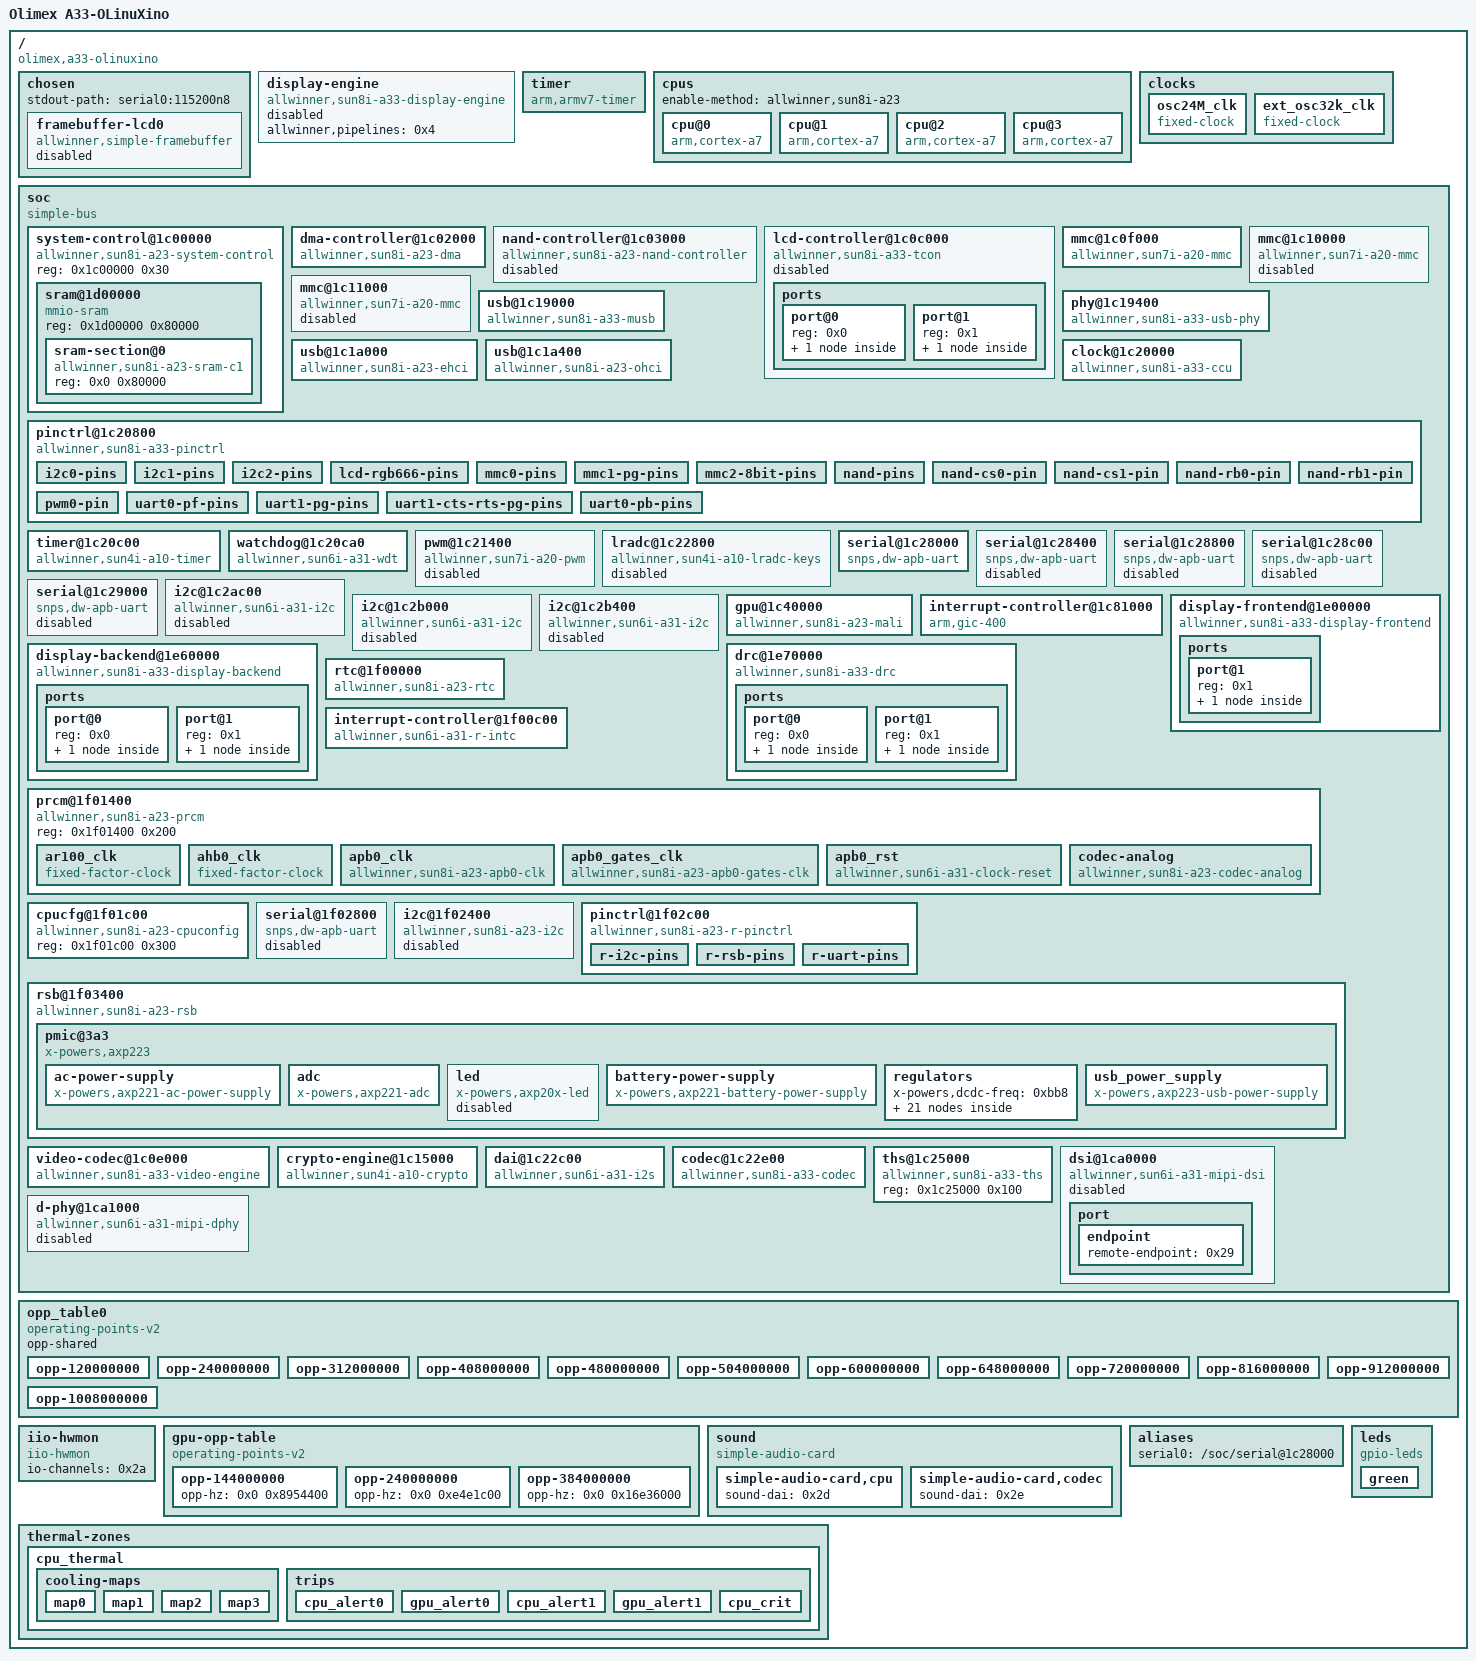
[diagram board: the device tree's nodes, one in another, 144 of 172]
/dts-v1/;

/ {
	interrupt-parent = <0x1>;
	#address-cells = <0x1>;
	#size-cells = <0x1>;
	model = "Olimex A33-OLinuXino";
	compatible = "olimex,a33-olinuxino", "allwinner,sun8i-a33";

	chosen {
		#address-cells = <0x1>;
		#size-cells = <0x1>;
		ranges;
		stdout-path = "serial0:115200n8";

		framebuffer-lcd0 {
			compatible = "allwinner,simple-framebuffer", "simple-framebuffer";
			allwinner,pipeline = "de_be0-lcd0";
			clocks = <0x2 0x26 0x2 0x28 0x2 0x57 0x2 0x55 0x2 0x54 0x2 0x62>;
			status = "disabled";
			vcc-lcd-supply = <0x3>;
			phandle = <0x38>;
		};
	};

	display-engine {
		allwinner,pipelines = <0x4>;
		status = "disabled";
		compatible = "allwinner,sun8i-a33-display-engine";
		phandle = <0x39>;
	};

	timer {
		compatible = "arm,armv7-timer";
		interrupts = <0x1 0xd 0xf08 0x1 0xe 0xf08 0x1 0xb 0xf08 0x1 0xa 0xf08>;
		clock-frequency = <0x16e3600>;
		arm,cpu-registers-not-fw-configured;
	};

	cpus {
		enable-method = "allwinner,sun8i-a23";
		#address-cells = <0x1>;
		#size-cells = <0x0>;

		cpu@0 {
			compatible = "arm,cortex-a7";
			device_type = "cpu";
			reg = <0x0>;
			clocks = <0x2 0x12>;
			clock-names = "cpu";
			operating-points-v2 = <0x5>;
			#cooling-cells = <0x2>;
			phandle = <0x30>;
		};

		cpu@1 {
			compatible = "arm,cortex-a7";
			device_type = "cpu";
			reg = <0x1>;
			clocks = <0x2 0x12>;
			clock-names = "cpu";
			operating-points-v2 = <0x5>;
			#cooling-cells = <0x2>;
			phandle = <0x31>;
		};

		cpu@2 {
			compatible = "arm,cortex-a7";
			device_type = "cpu";
			reg = <0x2>;
			clocks = <0x2 0x12>;
			clock-names = "cpu";
			operating-points-v2 = <0x5>;
			#cooling-cells = <0x2>;
			phandle = <0x32>;
		};

		cpu@3 {
			compatible = "arm,cortex-a7";
			device_type = "cpu";
			reg = <0x3>;
			clocks = <0x2 0x12>;
			clock-names = "cpu";
			operating-points-v2 = <0x5>;
			#cooling-cells = <0x2>;
			phandle = <0x33>;
		};
	};

	clocks {
		#address-cells = <0x1>;
		#size-cells = <0x1>;
		ranges;

		osc24M_clk {
			#clock-cells = <0x0>;
			compatible = "fixed-clock";
			clock-frequency = <0x16e3600>;
			clock-accuracy = <0xc350>;
			clock-output-names = "osc24M";
			phandle = <0x12>;
		};

		ext_osc32k_clk {
			#clock-cells = <0x0>;
			compatible = "fixed-clock";
			clock-frequency = <0x8000>;
			clock-accuracy = <0xc350>;
			clock-output-names = "ext-osc32k";
			phandle = <0x1e>;
		};
	};

	soc {
		compatible = "simple-bus";
		#address-cells = <0x1>;
		#size-cells = <0x1>;
		ranges;

		system-control@1c00000 {
			compatible = "allwinner,sun8i-a23-system-control";
			reg = <0x1c00000 0x30>;
			#address-cells = <0x1>;
			#size-cells = <0x1>;
			ranges;

			sram@1d00000 {
				compatible = "mmio-sram";
				reg = <0x1d00000 0x80000>;
				#address-cells = <0x1>;
				#size-cells = <0x1>;
				ranges = <0x0 0x1d00000 0x80000>;
				phandle = <0x3a>;

				sram-section@0 {
					compatible = "allwinner,sun8i-a23-sram-c1", "allwinner,sun4i-a10-sram-c1";
					reg = <0x0 0x80000>;
					phandle = <0x27>;
				};
			};
		};

		dma-controller@1c02000 {
			compatible = "allwinner,sun8i-a23-dma";
			reg = <0x1c02000 0x1000>;
			interrupts = <0x0 0x32 0x4>;
			clocks = <0x2 0x19>;
			resets = <0x2 0x6>;
			#dma-cells = <0x1>;
			phandle = <0x6>;
		};

		nand-controller@1c03000 {
			compatible = "allwinner,sun8i-a23-nand-controller";
			reg = <0x1c03000 0x1000>;
			interrupts = <0x0 0x46 0x4>;
			clocks = <0x2 0x1d 0x2 0x3b>;
			clock-names = "ahb", "mod";
			resets = <0x2 0xa>;
			reset-names = "ahb";
			dmas = <0x6 0x5>;
			dma-names = "rxtx";
			pinctrl-names = "default";
			pinctrl-0 = <0x7 0x8 0x9>;
			status = "disabled";
			#address-cells = <0x1>;
			#size-cells = <0x0>;
			phandle = <0x3b>;
		};

		lcd-controller@1c0c000 {
			reg = <0x1c0c000 0x1000>;
			interrupts = <0x0 0x56 0x4>;
			clocks = <0x2 0x26 0x2 0x57>;
			clock-names = "ahb", "tcon-ch0";
			clock-output-names = "tcon-pixel-clock";
			#clock-cells = <0x0>;
			resets = <0x2 0x13>;
			reset-names = "lcd";
			status = "disabled";
			compatible = "allwinner,sun8i-a33-tcon";
			phandle = <0x3c>;

			ports {
				#address-cells = <0x1>;
				#size-cells = <0x0>;

				port@0 {
					reg = <0x0>;
					phandle = <0x3d>;

					endpoint {
						remote-endpoint = <0xa>;
						phandle = <0x1d>;
					};
				};

				port@1 {
					reg = <0x1>;
					#address-cells = <0x1>;
					#size-cells = <0x0>;
					phandle = <0x3e>;

					endpoint@1 {
						reg = <0x1>;
						remote-endpoint = <0xb>;
						phandle = <0x29>;
					};
				};
			};
		};

		mmc@1c0f000 {
			compatible = "allwinner,sun7i-a20-mmc";
			reg = <0x1c0f000 0x1000>;
			clocks = <0x2 0x1a 0x2 0x3c 0x2 0x3e 0x2 0x3d>;
			clock-names = "ahb", "mmc", "output", "sample";
			resets = <0x2 0x7>;
			reset-names = "ahb";
			interrupts = <0x0 0x3c 0x4>;
			pinctrl-names = "default";
			pinctrl-0 = <0xc>;
			status = "okay";
			#address-cells = <0x1>;
			#size-cells = <0x0>;
			vmmc-supply = <0xd>;
			bus-width = <0x4>;
			cd-gpios = <0xe 0x1 0x4 0x1>;
			phandle = <0x3f>;
		};

		mmc@1c10000 {
			compatible = "allwinner,sun7i-a20-mmc";
			reg = <0x1c10000 0x1000>;
			clocks = <0x2 0x1b 0x2 0x3f 0x2 0x41 0x2 0x40>;
			clock-names = "ahb", "mmc", "output", "sample";
			resets = <0x2 0x8>;
			reset-names = "ahb";
			interrupts = <0x0 0x3d 0x4>;
			status = "disabled";
			#address-cells = <0x1>;
			#size-cells = <0x0>;
			phandle = <0x40>;
		};

		mmc@1c11000 {
			compatible = "allwinner,sun7i-a20-mmc";
			reg = <0x1c11000 0x1000>;
			clocks = <0x2 0x1c 0x2 0x42 0x2 0x44 0x2 0x43>;
			clock-names = "ahb", "mmc", "output", "sample";
			resets = <0x2 0x9>;
			reset-names = "ahb";
			interrupts = <0x0 0x3e 0x4>;
			status = "disabled";
			#address-cells = <0x1>;
			#size-cells = <0x0>;
			phandle = <0x41>;
		};

		usb@1c19000 {
			reg = <0x1c19000 0x400>;
			clocks = <0x2 0x22>;
			resets = <0x2 0xf>;
			interrupts = <0x0 0x47 0x4>;
			interrupt-names = "mc";
			phys = <0xf 0x0>;
			phy-names = "usb";
			extcon = <0xf 0x0>;
			dr_mode = "otg";
			status = "okay";
			compatible = "allwinner,sun8i-a33-musb";
			phandle = <0x42>;
		};

		phy@1c19400 {
			clocks = <0x2 0x4a 0x2 0x4b>;
			clock-names = "usb0_phy", "usb1_phy";
			resets = <0x2 0x0 0x2 0x1>;
			reset-names = "usb0_reset", "usb1_reset";
			status = "okay";
			#phy-cells = <0x1>;
			compatible = "allwinner,sun8i-a33-usb-phy";
			reg = <0x1c19400 0x14 0x1c1a800 0x4>;
			reg-names = "phy_ctrl", "pmu1";
			usb0_id_det-gpios = <0xe 0x1 0x3 0x0>;
			usb0_vbus_power-supply = <0x10>;
			usb0_vbus-supply = <0x11>;
			phandle = <0xf>;
		};

		usb@1c1a000 {
			compatible = "allwinner,sun8i-a23-ehci", "generic-ehci";
			reg = <0x1c1a000 0x100>;
			interrupts = <0x0 0x48 0x4>;
			clocks = <0x2 0x23>;
			resets = <0x2 0x10>;
			phys = <0xf 0x1>;
			status = "okay";
			phandle = <0x43>;
		};

		usb@1c1a400 {
			compatible = "allwinner,sun8i-a23-ohci", "generic-ohci";
			reg = <0x1c1a400 0x100>;
			interrupts = <0x0 0x49 0x4>;
			clocks = <0x2 0x24 0x2 0x4e>;
			resets = <0x2 0x11>;
			phys = <0xf 0x1>;
			status = "okay";
			phandle = <0x44>;
		};

		clock@1c20000 {
			reg = <0x1c20000 0x400>;
			clocks = <0x12 0x13 0x0>;
			clock-names = "hosc", "losc";
			#clock-cells = <0x1>;
			#reset-cells = <0x1>;
			compatible = "allwinner,sun8i-a33-ccu";
			phandle = <0x2>;
		};

		pinctrl@1c20800 {
			reg = <0x1c20800 0x400>;
			clocks = <0x2 0x30 0x12 0x13 0x0>;
			clock-names = "apb", "hosc", "losc";
			gpio-controller;
			interrupt-controller;
			#interrupt-cells = <0x3>;
			#gpio-cells = <0x3>;
			compatible = "allwinner,sun8i-a33-pinctrl";
			interrupts = <0x0 0xf 0x4 0x0 0x11 0x4>;
			phandle = <0xe>;

			i2c0-pins {
				pins = "PH2", "PH3";
				function = "i2c0";
				phandle = <0x15>;
			};

			i2c1-pins {
				pins = "PH4", "PH5";
				function = "i2c1";
				phandle = <0x16>;
			};

			i2c2-pins {
				pins = "PE12", "PE13";
				function = "i2c2";
				phandle = <0x17>;
			};

			lcd-rgb666-pins {
				pins = "PD2", "PD3", "PD4", "PD5", "PD6", "PD7", "PD10", "PD11", "PD12", "PD13", "PD14", "PD15", "PD18", "PD19", "PD20", "PD21", "PD22", "PD23", "PD24", "PD25", "PD26", "PD27";
				function = "lcd0";
				phandle = <0x45>;
			};

			mmc0-pins {
				pins = "PF0", "PF1", "PF2", "PF3", "PF4", "PF5";
				function = "mmc0";
				drive-strength = <0x1e>;
				bias-pull-up;
				phandle = <0xc>;
			};

			mmc1-pg-pins {
				pins = "PG0", "PG1", "PG2", "PG3", "PG4", "PG5";
				function = "mmc1";
				drive-strength = <0x1e>;
				bias-pull-up;
				phandle = <0x46>;
			};

			mmc2-8bit-pins {
				pins = "PC5", "PC6", "PC8", "PC9", "PC10", "PC11", "PC12", "PC13", "PC14", "PC15", "PC16";
				function = "mmc2";
				drive-strength = <0x1e>;
				bias-pull-up;
				phandle = <0x47>;
			};

			nand-pins {
				pins = "PC0", "PC1", "PC2", "PC5", "PC8", "PC9", "PC10", "PC11", "PC12", "PC13", "PC14", "PC15";
				function = "nand0";
				phandle = <0x7>;
			};

			nand-cs0-pin {
				pins = "PC4";
				function = "nand0";
				bias-pull-up;
				phandle = <0x8>;
			};

			nand-cs1-pin {
				pins = "PC3";
				function = "nand0";
				bias-pull-up;
				phandle = <0x48>;
			};

			nand-rb0-pin {
				pins = "PC6";
				function = "nand0";
				bias-pull-up;
				phandle = <0x9>;
			};

			nand-rb1-pin {
				pins = "PC7";
				function = "nand0";
				bias-pull-up;
				phandle = <0x49>;
			};

			pwm0-pin {
				pins = "PH0";
				function = "pwm0";
				phandle = <0x4a>;
			};

			uart0-pf-pins {
				pins = "PF2", "PF4";
				function = "uart0";
				phandle = <0x4b>;
			};

			uart1-pg-pins {
				pins = "PG6", "PG7";
				function = "uart1";
				phandle = <0x4c>;
			};

			uart1-cts-rts-pg-pins {
				pins = "PG8", "PG9";
				function = "uart1";
				phandle = <0x4d>;
			};

			uart0-pb-pins {
				pins = "PB0", "PB1";
				function = "uart0";
				phandle = <0x14>;
			};
		};

		timer@1c20c00 {
			compatible = "allwinner,sun4i-a10-timer";
			reg = <0x1c20c00 0xa0>;
			interrupts = <0x0 0x12 0x4 0x0 0x13 0x4>;
			clocks = <0x12>;
		};

		watchdog@1c20ca0 {
			compatible = "allwinner,sun6i-a31-wdt";
			reg = <0x1c20ca0 0x20>;
			interrupts = <0x0 0x19 0x4>;
			phandle = <0x4e>;
		};

		pwm@1c21400 {
			compatible = "allwinner,sun7i-a20-pwm";
			reg = <0x1c21400 0xc>;
			clocks = <0x12>;
			#pwm-cells = <0x3>;
			status = "disabled";
			phandle = <0x4f>;
		};

		lradc@1c22800 {
			compatible = "allwinner,sun4i-a10-lradc-keys";
			reg = <0x1c22800 0x100>;
			interrupts = <0x0 0x1e 0x4>;
			status = "disabled";
			phandle = <0x50>;
		};

		serial@1c28000 {
			compatible = "snps,dw-apb-uart";
			reg = <0x1c28000 0x400>;
			interrupts = <0x0 0x0 0x4>;
			reg-shift = <0x2>;
			reg-io-width = <0x4>;
			clocks = <0x2 0x36>;
			resets = <0x2 0x23>;
			dmas = <0x6 0x6 0x6 0x6>;
			dma-names = "rx", "tx";
			status = "okay";
			pinctrl-names = "default";
			pinctrl-0 = <0x14>;
			phandle = <0x51>;
		};

		serial@1c28400 {
			compatible = "snps,dw-apb-uart";
			reg = <0x1c28400 0x400>;
			interrupts = <0x0 0x1 0x4>;
			reg-shift = <0x2>;
			reg-io-width = <0x4>;
			clocks = <0x2 0x37>;
			resets = <0x2 0x24>;
			dmas = <0x6 0x7 0x6 0x7>;
			dma-names = "rx", "tx";
			status = "disabled";
			phandle = <0x52>;
		};

		serial@1c28800 {
			compatible = "snps,dw-apb-uart";
			reg = <0x1c28800 0x400>;
			interrupts = <0x0 0x2 0x4>;
			reg-shift = <0x2>;
			reg-io-width = <0x4>;
			clocks = <0x2 0x38>;
			resets = <0x2 0x25>;
			dmas = <0x6 0x8 0x6 0x8>;
			dma-names = "rx", "tx";
			status = "disabled";
			phandle = <0x53>;
		};

		serial@1c28c00 {
			compatible = "snps,dw-apb-uart";
			reg = <0x1c28c00 0x400>;
			interrupts = <0x0 0x3 0x4>;
			reg-shift = <0x2>;
			reg-io-width = <0x4>;
			clocks = <0x2 0x39>;
			resets = <0x2 0x26>;
			dmas = <0x6 0x9 0x6 0x9>;
			dma-names = "rx", "tx";
			status = "disabled";
			phandle = <0x54>;
		};

		serial@1c29000 {
			compatible = "snps,dw-apb-uart";
			reg = <0x1c29000 0x400>;
			interrupts = <0x0 0x4 0x4>;
			reg-shift = <0x2>;
			reg-io-width = <0x4>;
			clocks = <0x2 0x3a>;
			resets = <0x2 0x27>;
			dmas = <0x6 0xa 0x6 0xa>;
			dma-names = "rx", "tx";
			status = "disabled";
			phandle = <0x55>;
		};

		i2c@1c2ac00 {
			compatible = "allwinner,sun6i-a31-i2c";
			reg = <0x1c2ac00 0x400>;
			interrupts = <0x0 0x6 0x4>;
			clocks = <0x2 0x33>;
			resets = <0x2 0x20>;
			pinctrl-names = "default";
			pinctrl-0 = <0x15>;
			status = "disabled";
			#address-cells = <0x1>;
			#size-cells = <0x0>;
			phandle = <0x56>;
		};

		i2c@1c2b000 {
			compatible = "allwinner,sun6i-a31-i2c";
			reg = <0x1c2b000 0x400>;
			interrupts = <0x0 0x7 0x4>;
			clocks = <0x2 0x34>;
			resets = <0x2 0x21>;
			pinctrl-names = "default";
			pinctrl-0 = <0x16>;
			status = "disabled";
			#address-cells = <0x1>;
			#size-cells = <0x0>;
			phandle = <0x57>;
		};

		i2c@1c2b400 {
			compatible = "allwinner,sun6i-a31-i2c";
			reg = <0x1c2b400 0x400>;
			interrupts = <0x0 0x8 0x4>;
			clocks = <0x2 0x35>;
			resets = <0x2 0x22>;
			pinctrl-names = "default";
			pinctrl-0 = <0x17>;
			status = "disabled";
			#address-cells = <0x1>;
			#size-cells = <0x0>;
			phandle = <0x58>;
		};

		gpu@1c40000 {
			compatible = "allwinner,sun8i-a23-mali", "allwinner,sun7i-a20-mali", "arm,mali-400";
			reg = <0x1c40000 0x10000>;
			interrupts = <0x0 0x61 0x4 0x0 0x62 0x4 0x0 0x63 0x4 0x0 0x64 0x4 0x0 0x66 0x4 0x0 0x67 0x4 0x0 0x65 0x4>;
			interrupt-names = "gp", "gpmmu", "pp0", "ppmmu0", "pp1", "ppmmu1", "pmu";
			clocks = <0x2 0x2a 0x2 0x63>;
			clock-names = "bus", "core";
			resets = <0x2 0x17>;
			#cooling-cells = <0x2>;
			assigned-clocks = <0x2 0x63>;
			assigned-clock-rates = <0x16e36000>;
			operating-points-v2 = <0x18>;
			phandle = <0x36>;
		};

		interrupt-controller@1c81000 {
			compatible = "arm,gic-400";
			reg = <0x1c81000 0x1000 0x1c82000 0x2000 0x1c84000 0x2000 0x1c86000 0x2000>;
			interrupt-controller;
			#interrupt-cells = <0x3>;
			interrupts = <0x1 0x9 0xf04>;
			phandle = <0x1>;
		};

		display-frontend@1e00000 {
			reg = <0x1e00000 0x20000>;
			interrupts = <0x0 0x5d 0x4>;
			clocks = <0x2 0x29 0x2 0x56 0x2 0x53>;
			clock-names = "ahb", "mod", "ram";
			resets = <0x2 0x16>;
			compatible = "allwinner,sun8i-a33-display-frontend";
			phandle = <0x4>;

			ports {
				#address-cells = <0x1>;
				#size-cells = <0x0>;

				port@1 {
					reg = <0x1>;
					phandle = <0x59>;

					endpoint {
						remote-endpoint = <0x19>;
						phandle = <0x1a>;
					};
				};
			};
		};

		display-backend@1e60000 {
			reg = <0x1e60000 0x10000 0x1e80000 0x1000>;
			interrupts = <0x0 0x5f 0x4>;
			clocks = <0x2 0x28 0x2 0x55 0x2 0x54 0x2 0x2e>;
			clock-names = "ahb", "mod", "ram", "sat";
			resets = <0x2 0x15 0x2 0x1b>;
			compatible = "allwinner,sun8i-a33-display-backend";
			reg-names = "be", "sat";
			reset-names = "be", "sat";
			assigned-clocks = <0x2 0x55>;
			assigned-clock-rates = <0x11e1a300>;
			phandle = <0x5a>;

			ports {
				#address-cells = <0x1>;
				#size-cells = <0x0>;

				port@0 {
					reg = <0x0>;
					phandle = <0x5b>;

					endpoint {
						remote-endpoint = <0x1a>;
						phandle = <0x19>;
					};
				};

				port@1 {
					reg = <0x1>;
					phandle = <0x5c>;

					endpoint {
						remote-endpoint = <0x1b>;
						phandle = <0x1c>;
					};
				};
			};
		};

		drc@1e70000 {
			reg = <0x1e70000 0x10000>;
			interrupts = <0x0 0x5b 0x4>;
			clocks = <0x2 0x2d 0x2 0x62 0x2 0x52>;
			clock-names = "ahb", "mod", "ram";
			resets = <0x2 0x1a>;
			assigned-clocks = <0x2 0x62>;
			assigned-clock-rates = <0x11e1a300>;
			compatible = "allwinner,sun8i-a33-drc";
			phandle = <0x5d>;

			ports {
				#address-cells = <0x1>;
				#size-cells = <0x0>;

				port@0 {
					reg = <0x0>;
					phandle = <0x5e>;

					endpoint {
						remote-endpoint = <0x1c>;
						phandle = <0x1b>;
					};
				};

				port@1 {
					reg = <0x1>;
					phandle = <0x5f>;

					endpoint {
						remote-endpoint = <0x1d>;
						phandle = <0xa>;
					};
				};
			};
		};

		rtc@1f00000 {
			compatible = "allwinner,sun8i-a23-rtc";
			reg = <0x1f00000 0x400>;
			interrupts = <0x0 0x28 0x4 0x0 0x29 0x4>;
			clock-output-names = "osc32k", "osc32k-out";
			clocks = <0x1e>;
			#clock-cells = <0x1>;
			phandle = <0x13>;
		};

		interrupt-controller@1f00c00 {
			compatible = "allwinner,sun6i-a31-r-intc";
			interrupt-controller;
			#interrupt-cells = <0x2>;
			reg = <0x1f00c00 0x400>;
			interrupts = <0x0 0x20 0x4>;
			phandle = <0x26>;
		};

		prcm@1f01400 {
			compatible = "allwinner,sun8i-a23-prcm";
			reg = <0x1f01400 0x200>;

			ar100_clk {
				compatible = "fixed-factor-clock";
				#clock-cells = <0x0>;
				clock-div = <0x1>;
				clock-mult = <0x1>;
				clocks = <0x12>;
				clock-output-names = "ar100";
				phandle = <0x1f>;
			};

			ahb0_clk {
				compatible = "fixed-factor-clock";
				#clock-cells = <0x0>;
				clock-div = <0x1>;
				clock-mult = <0x1>;
				clocks = <0x1f>;
				clock-output-names = "ahb0";
				phandle = <0x20>;
			};

			apb0_clk {
				compatible = "allwinner,sun8i-a23-apb0-clk";
				#clock-cells = <0x0>;
				clocks = <0x20>;
				clock-output-names = "apb0";
				phandle = <0x21>;
			};

			apb0_gates_clk {
				compatible = "allwinner,sun8i-a23-apb0-gates-clk";
				#clock-cells = <0x1>;
				clocks = <0x21>;
				clock-output-names = "apb0_pio", "apb0_timer", "apb0_rsb", "apb0_uart", "apb0_i2c";
				phandle = <0x22>;
			};

			apb0_rst {
				compatible = "allwinner,sun6i-a31-clock-reset";
				#reset-cells = <0x1>;
				phandle = <0x23>;
			};

			codec-analog {
				compatible = "allwinner,sun8i-a23-codec-analog";
				phandle = <0x2c>;
			};
		};

		cpucfg@1f01c00 {
			compatible = "allwinner,sun8i-a23-cpuconfig";
			reg = <0x1f01c00 0x300>;
		};

		serial@1f02800 {
			compatible = "snps,dw-apb-uart";
			reg = <0x1f02800 0x400>;
			interrupts = <0x0 0x26 0x4>;
			reg-shift = <0x2>;
			reg-io-width = <0x4>;
			clocks = <0x22 0x4>;
			resets = <0x23 0x4>;
			status = "disabled";
			phandle = <0x60>;
		};

		i2c@1f02400 {
			compatible = "allwinner,sun8i-a23-i2c", "allwinner,sun6i-a31-i2c";
			reg = <0x1f02400 0x400>;
			interrupts = <0x0 0x2c 0x4>;
			pinctrl-names = "default";
			pinctrl-0 = <0x24>;
			clocks = <0x22 0x6>;
			resets = <0x23 0x6>;
			status = "disabled";
			#address-cells = <0x1>;
			#size-cells = <0x0>;
			phandle = <0x61>;
		};

		pinctrl@1f02c00 {
			compatible = "allwinner,sun8i-a23-r-pinctrl";
			reg = <0x1f02c00 0x400>;
			interrupts = <0x0 0x2d 0x4>;
			clocks = <0x22 0x0 0x12 0x13 0x0>;
			clock-names = "apb", "hosc", "losc";
			resets = <0x23 0x0>;
			gpio-controller;
			interrupt-controller;
			#interrupt-cells = <0x3>;
			#gpio-cells = <0x3>;
			phandle = <0x62>;

			r-i2c-pins {
				pins = "PL0", "PL1";
				function = "s_i2c";
				bias-pull-up;
				phandle = <0x24>;
			};

			r-rsb-pins {
				pins = "PL0", "PL1";
				function = "s_rsb";
				drive-strength = <0x14>;
				bias-pull-up;
				phandle = <0x25>;
			};

			r-uart-pins {
				pins = "PL2", "PL3";
				function = "s_uart";
				phandle = <0x63>;
			};
		};

		rsb@1f03400 {
			compatible = "allwinner,sun8i-a23-rsb";
			reg = <0x1f03400 0x400>;
			interrupts = <0x0 0x27 0x4>;
			clocks = <0x22 0x3>;
			clock-frequency = <0x2dc6c0>;
			resets = <0x23 0x3>;
			pinctrl-names = "default";
			pinctrl-0 = <0x25>;
			status = "okay";
			#address-cells = <0x1>;
			#size-cells = <0x0>;
			phandle = <0x64>;

			pmic@3a3 {
				compatible = "x-powers,axp223";
				reg = <0x3a3>;
				interrupt-parent = <0x26>;
				interrupts = <0x0 0x8>;
				eldoin-supply = <0xd>;
				x-powers,drive-vbus-en;
				interrupt-controller;
				#interrupt-cells = <0x1>;
				phandle = <0x65>;

				ac-power-supply {
					compatible = "x-powers,axp221-ac-power-supply";
					status = "okay";
					phandle = <0x66>;
				};

				adc {
					compatible = "x-powers,axp221-adc";
					#io-channel-cells = <0x1>;
					phandle = <0x67>;
				};

				led {
					compatible = "x-powers,axp20x-led";
					status = "disabled";
					phandle = <0x68>;
				};

				battery-power-supply {
					compatible = "x-powers,axp221-battery-power-supply";
					status = "okay";
					phandle = <0x69>;
				};

				regulators {
					x-powers,dcdc-freq = <0xbb8>;

					dcdc1 {
						regulator-name = "vcc-3v3";
						regulator-always-on;
						regulator-min-microvolt = <0x325aa0>;
						regulator-max-microvolt = <0x325aa0>;
						phandle = <0xd>;
					};

					dcdc2 {
						regulator-name = "vdd-sys";
						regulator-always-on;
						regulator-min-microvolt = <0xdbba0>;
						regulator-max-microvolt = <0x155cc0>;
						phandle = <0x6a>;
					};

					dcdc3 {
						regulator-name = "vdd-cpu";
						regulator-always-on;
						regulator-min-microvolt = <0xdbba0>;
						regulator-max-microvolt = <0x155cc0>;
						phandle = <0x6b>;
					};

					dcdc4 {
						regulator-name = "dcdc4";
						phandle = <0x6c>;
					};

					dcdc5 {
						regulator-name = "vcc-dram";
						regulator-always-on;
						regulator-min-microvolt = <0x16e360>;
						regulator-max-microvolt = <0x16e360>;
						phandle = <0x6d>;
					};

					dc1sw {
						regulator-name = "vcc-lcd";
						phandle = <0x3>;
					};

					dc5ldo {
						regulator-name = "vdd-cpus";
						regulator-always-on;
						regulator-min-microvolt = <0xdbba0>;
						regulator-max-microvolt = <0x155cc0>;
						phandle = <0x6e>;
					};

					aldo1 {
						regulator-name = "vcc-io";
						regulator-always-on;
						regulator-min-microvolt = <0x325aa0>;
						regulator-max-microvolt = <0x325aa0>;
						phandle = <0x6f>;
					};

					aldo2 {
						regulator-name = "vdd-dll";
						regulator-always-on;
						regulator-min-microvolt = <0x23dbb0>;
						regulator-max-microvolt = <0x286f90>;
						phandle = <0x70>;
					};

					aldo3 {
						regulator-name = "vcc-avcc";
						regulator-always-on;
						regulator-min-microvolt = <0x325aa0>;
						regulator-max-microvolt = <0x325aa0>;
						phandle = <0x71>;
					};

					dldo1 {
						regulator-name = "dldo1";
						phandle = <0x72>;
					};

					dldo2 {
						regulator-name = "dldo2";
						phandle = <0x73>;
					};

					dldo3 {
						regulator-name = "dldo3";
						phandle = <0x74>;
					};

					dldo4 {
						regulator-name = "dldo4";
						phandle = <0x75>;
					};

					eldo1 {
						regulator-name = "eldo1";
						phandle = <0x76>;
					};

					eldo2 {
						regulator-name = "eldo2";
						phandle = <0x77>;
					};

					eldo3 {
						regulator-name = "eldo3";
						phandle = <0x78>;
					};

					ldo_io0 {
						regulator-name = "ldo_io0";
						status = "disabled";
						phandle = <0x79>;
					};

					ldo_io1 {
						regulator-name = "ldo_io1";
						status = "disabled";
						phandle = <0x7a>;
					};

					rtc_ldo {
						regulator-always-on;
						regulator-min-microvolt = <0x2dc6c0>;
						regulator-max-microvolt = <0x2dc6c0>;
						regulator-name = "vcc-rtc";
						phandle = <0x7b>;
					};

					drivevbus {
						regulator-name = "usb0-vbus";
						status = "okay";
						phandle = <0x11>;
					};
				};

				usb_power_supply {
					compatible = "x-powers,axp223-usb-power-supply";
					status = "okay";
					phandle = <0x10>;
				};
			};
		};

		video-codec@1c0e000 {
			compatible = "allwinner,sun8i-a33-video-engine";
			reg = <0x1c0e000 0x1000>;
			clocks = <0x2 0x25 0x2 0x5b 0x2 0x50>;
			clock-names = "ahb", "mod", "ram";
			resets = <0x2 0x12>;
			interrupts = <0x0 0x3a 0x4>;
			allwinner,sram = <0x27 0x1>;
		};

		crypto-engine@1c15000 {
			compatible = "allwinner,sun4i-a10-crypto";
			reg = <0x1c15000 0x1000>;
			interrupts = <0x0 0x50 0x4>;
			clocks = <0x2 0x18 0x2 0x45>;
			clock-names = "ahb", "mod";
			resets = <0x2 0x5>;
			reset-names = "ahb";
			phandle = <0x7c>;
		};

		dai@1c22c00 {
			#sound-dai-cells = <0x0>;
			compatible = "allwinner,sun6i-a31-i2s";
			reg = <0x1c22c00 0x200>;
			interrupts = <0x0 0x1d 0x4>;
			clocks = <0x2 0x2f 0x2 0x5c>;
			clock-names = "apb", "mod";
			resets = <0x2 0x1d>;
			dmas = <0x6 0xf 0x6 0xf>;
			dma-names = "rx", "tx";
			status = "okay";
			phandle = <0x2d>;
		};

		codec@1c22e00 {
			#sound-dai-cells = <0x0>;
			compatible = "allwinner,sun8i-a33-codec";
			reg = <0x1c22e00 0x400>;
			interrupts = <0x0 0x1d 0x4>;
			clocks = <0x2 0x2f 0x2 0x5c>;
			clock-names = "bus", "mod";
			status = "okay";
			phandle = <0x2e>;
		};

		ths@1c25000 {
			compatible = "allwinner,sun8i-a33-ths";
			reg = <0x1c25000 0x100>;
			#thermal-sensor-cells = <0x0>;
			#io-channel-cells = <0x0>;
			phandle = <0x2a>;
		};

		dsi@1ca0000 {
			compatible = "allwinner,sun6i-a31-mipi-dsi";
			reg = <0x1ca0000 0x1000>;
			interrupts = <0x0 0x59 0x4>;
			clocks = <0x2 0x17 0x2 0x60>;
			clock-names = "bus", "mod";
			resets = <0x2 0x4>;
			phys = <0x28>;
			phy-names = "dphy";
			status = "disabled";
			#address-cells = <0x1>;
			#size-cells = <0x0>;
			phandle = <0x7d>;

			port {

				endpoint {
					remote-endpoint = <0x29>;
					phandle = <0xb>;
				};
			};
		};

		d-phy@1ca1000 {
			compatible = "allwinner,sun6i-a31-mipi-dphy";
			reg = <0x1ca1000 0x1000>;
			clocks = <0x2 0x17 0x2 0x61>;
			clock-names = "bus", "mod";
			resets = <0x2 0x4>;
			status = "disabled";
			#phy-cells = <0x0>;
			phandle = <0x28>;
		};
	};

	opp_table0 {
		compatible = "operating-points-v2";
		opp-shared;
		phandle = <0x5>;

		opp-120000000 {
			opp-hz = <0x0 0x7270e00>;
			opp-microvolt = <0xfde80>;
			clock-latency-ns = <0x3b9b0>;
		};

		opp-240000000 {
			opp-hz = <0x0 0xe4e1c00>;
			opp-microvolt = <0xfde80>;
			clock-latency-ns = <0x3b9b0>;
		};

		opp-312000000 {
			opp-hz = <0x0 0x1298be00>;
			opp-microvolt = <0xfde80>;
			clock-latency-ns = <0x3b9b0>;
		};

		opp-408000000 {
			opp-hz = <0x0 0x18519600>;
			opp-microvolt = <0xfde80>;
			clock-latency-ns = <0x3b9b0>;
		};

		opp-480000000 {
			opp-hz = <0x0 0x1c9c3800>;
			opp-microvolt = <0xfde80>;
			clock-latency-ns = <0x3b9b0>;
		};

		opp-504000000 {
			opp-hz = <0x0 0x1e0a6e00>;
			opp-microvolt = <0xfde80>;
			clock-latency-ns = <0x3b9b0>;
		};

		opp-600000000 {
			opp-hz = <0x0 0x23c34600>;
			opp-microvolt = <0xfde80>;
			clock-latency-ns = <0x3b9b0>;
		};

		opp-648000000 {
			opp-hz = <0x0 0x269fb200>;
			opp-microvolt = <0xfde80>;
			clock-latency-ns = <0x3b9b0>;
		};

		opp-720000000 {
			opp-hz = <0x0 0x2aea5400>;
			opp-microvolt = <0x10c8e0>;
			clock-latency-ns = <0x3b9b0>;
		};

		opp-816000000 {
			opp-hz = <0x0 0x30a32c00>;
			opp-microvolt = <0x10c8e0>;
			clock-latency-ns = <0x3b9b0>;
		};

		opp-912000000 {
			opp-hz = <0x0 0x365c0400>;
			opp-microvolt = <0x124f80>;
			clock-latency-ns = <0x3b9b0>;
		};

		opp-1008000000 {
			opp-hz = <0x0 0x3c14dc00>;
			opp-microvolt = <0x124f80>;
			clock-latency-ns = <0x3b9b0>;
		};
	};

	iio-hwmon {
		compatible = "iio-hwmon";
		io-channels = <0x2a>;
	};

	gpu-opp-table {
		compatible = "operating-points-v2";
		phandle = <0x18>;

		opp-144000000 {
			opp-hz = <0x0 0x8954400>;
		};

		opp-240000000 {
			opp-hz = <0x0 0xe4e1c00>;
		};

		opp-384000000 {
			opp-hz = <0x0 0x16e36000>;
		};
	};

	sound {
		compatible = "simple-audio-card";
		simple-audio-card,name = "sun8i-a33-audio";
		simple-audio-card,format = "i2s";
		simple-audio-card,frame-master = <0x2b>;
		simple-audio-card,bitclock-master = <0x2b>;
		simple-audio-card,mclk-fs = <0x80>;
		simple-audio-card,aux-devs = <0x2c>;
		simple-audio-card,routing = "Left DAC", "AIF1 Slot 0 Left", "Right DAC", "AIF1 Slot 0 Right", "HP", "HPCOM", "Headphone Jack", "HP", "MIC1", "Microphone Jack", "Microphone Jack", "MBIAS";
		status = "okay";
		simple-audio-card,widgets = "Microphone", "Microphone Jack", "Headphone", "Headphone Jack";
		phandle = <0x7e>;

		simple-audio-card,cpu {
			sound-dai = <0x2d>;
		};

		simple-audio-card,codec {
			sound-dai = <0x2e>;
			phandle = <0x2b>;
		};
	};

	thermal-zones {

		cpu_thermal {
			polling-delay-passive = <0xfa>;
			polling-delay = <0x3e8>;
			thermal-sensors = <0x2a>;

			cooling-maps {

				map0 {
					trip = <0x2f>;
					cooling-device = <0x30 0xffffffff 0xffffffff 0x31 0xffffffff 0xffffffff 0x32 0xffffffff 0xffffffff 0x33 0xffffffff 0xffffffff>;
				};

				map1 {
					trip = <0x34>;
					cooling-device = <0x30 0xffffffff 0xffffffff 0x31 0xffffffff 0xffffffff 0x32 0xffffffff 0xffffffff 0x33 0xffffffff 0xffffffff>;
				};

				map2 {
					trip = <0x35>;
					cooling-device = <0x36 0x1 0xffffffff>;
				};

				map3 {
					trip = <0x37>;
					cooling-device = <0x36 0x2 0xffffffff>;
				};
			};

			trips {

				cpu_alert0 {
					temperature = <0x124f8>;
					hysteresis = <0x7d0>;
					type = "passive";
					phandle = <0x2f>;
				};

				gpu_alert0 {
					temperature = <0x14c08>;
					hysteresis = <0x7d0>;
					type = "passive";
					phandle = <0x35>;
				};

				cpu_alert1 {
					temperature = <0x15f90>;
					hysteresis = <0x7d0>;
					type = "hot";
					phandle = <0x34>;
				};

				gpu_alert1 {
					temperature = <0x17318>;
					hysteresis = <0x7d0>;
					type = "hot";
					phandle = <0x37>;
				};

				cpu_crit {
					temperature = <0x1adb0>;
					hysteresis = <0x7d0>;
					type = "critical";
					phandle = <0x7f>;
				};
			};
		};
	};

	aliases {
		serial0 = "/soc/serial@1c28000";
	};

	leds {
		compatible = "gpio-leds";

		green {
			label = "a33-olinuxino:green:usr";
			gpios = <0xe 0x1 0x7 0x0>;
		};
	};

	__symbols__ {
		simplefb_lcd = "/chosen/framebuffer-lcd0";
		de = "/display-engine";
		cpu0 = "/cpus/cpu@0";
		cpu1 = "/cpus/cpu@1";
		cpu2 = "/cpus/cpu@2";
		cpu3 = "/cpus/cpu@3";
		osc24M = "/clocks/osc24M_clk";
		ext_osc32k = "/clocks/ext_osc32k_clk";
		sram_c = "/soc/system-control@1c00000/sram@1d00000";
		ve_sram = "/soc/system-control@1c00000/sram@1d00000/sram-section@0";
		dma = "/soc/dma-controller@1c02000";
		nfc = "/soc/nand-controller@1c03000";
		tcon0 = "/soc/lcd-controller@1c0c000";
		tcon0_in = "/soc/lcd-controller@1c0c000/ports/port@0";
		tcon0_in_drc0 = "/soc/lcd-controller@1c0c000/ports/port@0/endpoint";
		tcon0_out = "/soc/lcd-controller@1c0c000/ports/port@1";
		tcon0_out_dsi = "/soc/lcd-controller@1c0c000/ports/port@1/endpoint@1";
		mmc0 = "/soc/mmc@1c0f000";
		mmc1 = "/soc/mmc@1c10000";
		mmc2 = "/soc/mmc@1c11000";
		usb_otg = "/soc/usb@1c19000";
		usbphy = "/soc/phy@1c19400";
		ehci0 = "/soc/usb@1c1a000";
		ohci0 = "/soc/usb@1c1a400";
		ccu = "/soc/clock@1c20000";
		pio = "/soc/pinctrl@1c20800";
		i2c0_pins = "/soc/pinctrl@1c20800/i2c0-pins";
		i2c1_pins = "/soc/pinctrl@1c20800/i2c1-pins";
		i2c2_pins = "/soc/pinctrl@1c20800/i2c2-pins";
		lcd_rgb666_pins = "/soc/pinctrl@1c20800/lcd-rgb666-pins";
		mmc0_pins = "/soc/pinctrl@1c20800/mmc0-pins";
		mmc1_pg_pins = "/soc/pinctrl@1c20800/mmc1-pg-pins";
		mmc2_8bit_pins = "/soc/pinctrl@1c20800/mmc2-8bit-pins";
		nand_pins = "/soc/pinctrl@1c20800/nand-pins";
		nand_cs0_pin = "/soc/pinctrl@1c20800/nand-cs0-pin";
		nand_cs1_pin = "/soc/pinctrl@1c20800/nand-cs1-pin";
		nand_rb0_pin = "/soc/pinctrl@1c20800/nand-rb0-pin";
		nand_rb1_pin = "/soc/pinctrl@1c20800/nand-rb1-pin";
		pwm0_pin = "/soc/pinctrl@1c20800/pwm0-pin";
		uart0_pf_pins = "/soc/pinctrl@1c20800/uart0-pf-pins";
		uart1_pg_pins = "/soc/pinctrl@1c20800/uart1-pg-pins";
		uart1_cts_rts_pg_pins = "/soc/pinctrl@1c20800/uart1-cts-rts-pg-pins";
		uart0_pb_pins = "/soc/pinctrl@1c20800/uart0-pb-pins";
		wdt0 = "/soc/watchdog@1c20ca0";
		pwm = "/soc/pwm@1c21400";
		lradc = "/soc/lradc@1c22800";
		uart0 = "/soc/serial@1c28000";
		uart1 = "/soc/serial@1c28400";
		uart2 = "/soc/serial@1c28800";
		uart3 = "/soc/serial@1c28c00";
		uart4 = "/soc/serial@1c29000";
		i2c0 = "/soc/i2c@1c2ac00";
		i2c1 = "/soc/i2c@1c2b000";
		i2c2 = "/soc/i2c@1c2b400";
		mali = "/soc/gpu@1c40000";
		gic = "/soc/interrupt-controller@1c81000";
		fe0 = "/soc/display-frontend@1e00000";
		fe0_out = "/soc/display-frontend@1e00000/ports/port@1";
		fe0_out_be0 = "/soc/display-frontend@1e00000/ports/port@1/endpoint";
		be0 = "/soc/display-backend@1e60000";
		be0_in = "/soc/display-backend@1e60000/ports/port@0";
		be0_in_fe0 = "/soc/display-backend@1e60000/ports/port@0/endpoint";
		be0_out = "/soc/display-backend@1e60000/ports/port@1";
		be0_out_drc0 = "/soc/display-backend@1e60000/ports/port@1/endpoint";
		drc0 = "/soc/drc@1e70000";
		drc0_in = "/soc/drc@1e70000/ports/port@0";
		drc0_in_be0 = "/soc/drc@1e70000/ports/port@0/endpoint";
		drc0_out = "/soc/drc@1e70000/ports/port@1";
		drc0_out_tcon0 = "/soc/drc@1e70000/ports/port@1/endpoint";
		rtc = "/soc/rtc@1f00000";
		nmi_intc = "/soc/interrupt-controller@1f00c00";
		ar100 = "/soc/prcm@1f01400/ar100_clk";
		ahb0 = "/soc/prcm@1f01400/ahb0_clk";
		apb0 = "/soc/prcm@1f01400/apb0_clk";
		apb0_gates = "/soc/prcm@1f01400/apb0_gates_clk";
		apb0_rst = "/soc/prcm@1f01400/apb0_rst";
		codec_analog = "/soc/prcm@1f01400/codec-analog";
		r_uart = "/soc/serial@1f02800";
		r_i2c = "/soc/i2c@1f02400";
		r_pio = "/soc/pinctrl@1f02c00";
		r_i2c_pins = "/soc/pinctrl@1f02c00/r-i2c-pins";
		r_rsb_pins = "/soc/pinctrl@1f02c00/r-rsb-pins";
		r_uart_pins_a = "/soc/pinctrl@1f02c00/r-uart-pins";
		r_rsb = "/soc/rsb@1f03400";
		axp22x = "/soc/rsb@1f03400/pmic@3a3";
		ac_power_supply = "/soc/rsb@1f03400/pmic@3a3/ac-power-supply";
		axp_adc = "/soc/rsb@1f03400/pmic@3a3/adc";
		axp_led = "/soc/rsb@1f03400/pmic@3a3/led";
		battery_power_supply = "/soc/rsb@1f03400/pmic@3a3/battery-power-supply";
		reg_dcdc1 = "/soc/rsb@1f03400/pmic@3a3/regulators/dcdc1";
		reg_dcdc2 = "/soc/rsb@1f03400/pmic@3a3/regulators/dcdc2";
		reg_dcdc3 = "/soc/rsb@1f03400/pmic@3a3/regulators/dcdc3";
		reg_dcdc4 = "/soc/rsb@1f03400/pmic@3a3/regulators/dcdc4";
		reg_dcdc5 = "/soc/rsb@1f03400/pmic@3a3/regulators/dcdc5";
		reg_dc1sw = "/soc/rsb@1f03400/pmic@3a3/regulators/dc1sw";
		reg_dc5ldo = "/soc/rsb@1f03400/pmic@3a3/regulators/dc5ldo";
		reg_aldo1 = "/soc/rsb@1f03400/pmic@3a3/regulators/aldo1";
		reg_aldo2 = "/soc/rsb@1f03400/pmic@3a3/regulators/aldo2";
		reg_aldo3 = "/soc/rsb@1f03400/pmic@3a3/regulators/aldo3";
		reg_dldo1 = "/soc/rsb@1f03400/pmic@3a3/regulators/dldo1";
		reg_dldo2 = "/soc/rsb@1f03400/pmic@3a3/regulators/dldo2";
		reg_dldo3 = "/soc/rsb@1f03400/pmic@3a3/regulators/dldo3";
		reg_dldo4 = "/soc/rsb@1f03400/pmic@3a3/regulators/dldo4";
		reg_eldo1 = "/soc/rsb@1f03400/pmic@3a3/regulators/eldo1";
		reg_eldo2 = "/soc/rsb@1f03400/pmic@3a3/regulators/eldo2";
		reg_eldo3 = "/soc/rsb@1f03400/pmic@3a3/regulators/eldo3";
		reg_ldo_io0 = "/soc/rsb@1f03400/pmic@3a3/regulators/ldo_io0";
		reg_ldo_io1 = "/soc/rsb@1f03400/pmic@3a3/regulators/ldo_io1";
		reg_rtc_ldo = "/soc/rsb@1f03400/pmic@3a3/regulators/rtc_ldo";
		reg_drivevbus = "/soc/rsb@1f03400/pmic@3a3/regulators/drivevbus";
		usb_power_supply = "/soc/rsb@1f03400/pmic@3a3/usb_power_supply";
		crypto = "/soc/crypto-engine@1c15000";
		dai = "/soc/dai@1c22c00";
		codec = "/soc/codec@1c22e00";
		ths = "/soc/ths@1c25000";
		dsi = "/soc/dsi@1ca0000";
		dsi_in_tcon0 = "/soc/dsi@1ca0000/port/endpoint";
		dphy = "/soc/d-phy@1ca1000";
		cpu0_opp_table = "/opp_table0";
		mali_opp_table = "/gpu-opp-table";
		sound = "/sound";
		link_codec = "/sound/simple-audio-card,codec";
		cpu_alert0 = "/thermal-zones/cpu_thermal/trips/cpu_alert0";
		gpu_alert0 = "/thermal-zones/cpu_thermal/trips/gpu_alert0";
		cpu_alert1 = "/thermal-zones/cpu_thermal/trips/cpu_alert1";
		gpu_alert1 = "/thermal-zones/cpu_thermal/trips/gpu_alert1";
		cpu_crit = "/thermal-zones/cpu_thermal/trips/cpu_crit";
	};
};
